AUTOSAR XML (schema 00051)
package /TPC_Composition/Components
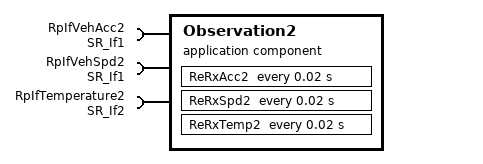
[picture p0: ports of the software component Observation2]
  application sw component type Observation2
    require port RpIfVehAcc2: required-interface=SR_If1, nonqueued-receiver-com-spec{data-element=Acc, init-value=222}
    require port RpIfVehSpd2: required-interface=SR_If1, nonqueued-receiver-com-spec{data-element=Spd, init-value=444}
    require port RpIfTemperature2: required-interface=SR_If2, queued-receiver-com-spec{data-element=Temp, queue-length=10}
    behavior SWC_Observation2_InternalBehavior
      runnable ReRxAcc2
        data-receive-point-by-arguments:
          access DataReceivePointByArgument_PpIfVehMov_Acci: return-value-provision=RETURN-VALUE-PROVIDED, accessed-variable=RpIfVehAcc2.Acc
      runnable ReRxSpd2
        data-receive-point-by-values:
          access DataReceivePointByArgument_PpIfVehMov_Spd: accessed-variable=RpIfVehSpd2.Spd
      runnable ReRxTemp2
        data-receive-point-by-arguments:
          access DataReceivePointByArgument_PpIfTemperature_Temp: accessed-variable=RpIfTemperature2.Temp
        wait point ReRxTemp_WaitPoint: timeout=0.01, trigger=Obv_Ev_DR
      timing event EvTiAcc_20ms: start-on-event=ReRxAcc2, period=0.02
      timing event EvTiSpd_20ms: start-on-event=ReRxSpd2, period=0.02
      timing event EvTiTemp_20ms: start-on-event=ReRxTemp2, period=0.02
      data received event Obv_Ev_DR: data=RpIfTemperature2.Temp
      port-api-options:
        port=RpIfVehAcc2, transformer-status-forwarding=TRANSFORMER-STATUS-FORWARDING, error-handling=TRANSFORMER-ERROR-HANDLING
        port=RpIfTemperature2, error-handling=TRANSFORMER-ERROR-HANDLING
